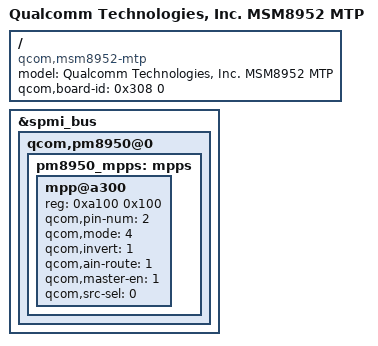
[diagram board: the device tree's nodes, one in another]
/*
 * Copyright (c) 2015, The Linux Foundation. All rights reserved.
 *
 * This program is free software; you can redistribute it and/or modify
 * it under the terms of the GNU General Public License version 2 and
 * only version 2 as published by the Free Software Foundation.
 *
 * This program is distributed in the hope that it will be useful,
 * but WITHOUT ANY WARRANTY; without even the implied warranty of
 * MERCHANTABILITY or FITNESS FOR A PARTICULAR PURPOSE.  See the
 * GNU General Public License for more details.
 */

/dts-v1/;

#include "msm8952-b3_rgs_ca.dtsi"

/ {
	model = "Qualcomm Technologies, Inc. MSM8952 MTP";
	compatible = "qcom,msm8952-mtp", "qcom,msm8952", "qcom,mtp", "lge,msm8952-p1v_att_us";
	qcom,board-id= <0x008 0>;
	qcom,board-id= <0x108 0>;
	qcom,board-id= <0x208 0>;
	qcom,board-id= <0x308 0>; /* rev_a */
};

&spmi_bus {
	qcom,pm8950@0 {
		pm8950_mpps: mpps {
			mpp@a300 {
				/* MPP2 - PA_THERM config */
				reg = <0xa100 0x100>;
				qcom,pin-num = <2>;
				qcom,mode = <4>; /* AIN input */
				qcom,invert = <1>; /* Enable MPP */
				qcom,ain-route = <1>; /* AMUX 6 */
				qcom,master-en = <1>;
				qcom,src-sel = <0>; /* Function constant */
			};
		};
	};
};
